# STM32N645 register map
File version: 1.0
CPU: CM55 r0p1, little endian, no MPU, FPU, vendor SysTick, 8 interrupt priority bits
Registers are 32-bit, read-write, reset 0x0 unless marked. A register's access mark holds for its fields unless they carry their own. Offsets are from the block's base; [hi:lo] are bit positions; {n}, {i} and the like mark numbered series; 'fields as' and 'values as' point back to an identical list.

## MDF1 — MDF register block
Base 0x42025000
Same registers: MDF1_S 0x52025000
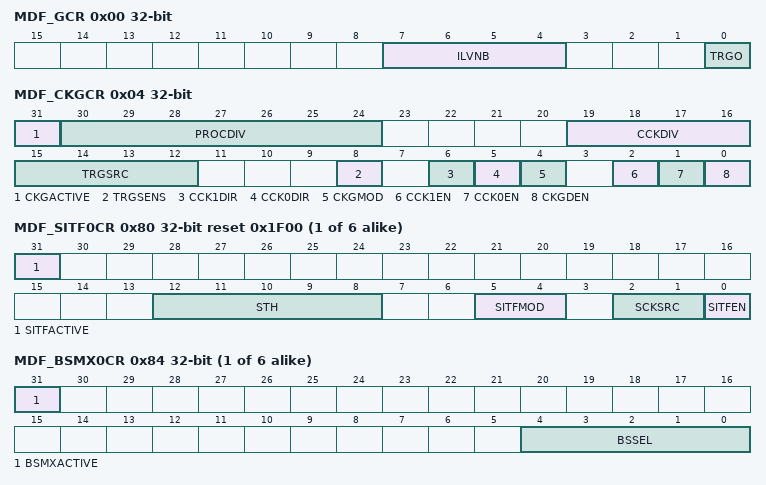
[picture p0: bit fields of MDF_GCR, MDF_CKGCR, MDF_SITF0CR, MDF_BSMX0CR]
0x00 MDF_GCR — MDF global control register
  [7:4] ILVNB — Interleaved number
    0=Interleaved-transfer mode disabled; 1=Data from DFLT0 and DFLT1 are interleaved; 2=Data from DFLT0, DFLT1 and DFLT2 are interleaved; 15=Data from DFLT0 to DFLT15 are interleaved
  [0] TRGO — Trigger output control
    0=Write 0 has no effect. Read 0 means that the trigger can be set again to 1.; 1=Write 1 generates a positive pulse on mdf_trgo signal and triggers the acquisition on the enabled filters having ACQMOD[2:0] = 0x1 and selecting TRGO as trigger. Read 1 means that the trigger pulse is still active.
0x04 MDF_CKGCR access per field — MDF clock generator control register
  [31] CKGACTIVE ro — Clock generator active flag
    0=The clock generator is not active and can be configured if needed; 1=The clock generator is active and protected fields cannot be configured
  [30:24] PROCDIV rw — Divider to control the serial interface clock
    0=mdf_ker_ck provided to the SITF; 1=mdf_ker_ck/2 provided to the SITF
  [19:16] CCKDIV rw — Divider to control the MDF_CCK clock
    0=The MDF_CCK clock is mdf_proc_ck; 1=The MDF_CCK clock is mdf_proc_ck / 2; 2=The MDF_CCK clock is mdf_proc_ck / 3; 15=The MDF_CCK clock is mdf_proc_ck / 16
  [15:12] TRGSRC rw — Digital filter trigger signal selection
    2=mdf_trg[0] selected; 3=mdf_trg[1] selected; 15=mdf_trg[13] selected
  [8] TRGSENS rw — CKGEN trigger sensitivity selection
    0=A rising edge event triggers the activation of CKGEN dividers; 1=A falling edge even triggers the activation of CKGEN dividers
  [6] CCK1DIR rw — MDF_CCK1 direction
    0=MDF_CCK1 pin direction is in input; 1=MDF_CCK1 pin direction is in output
  [5] CCK0DIR rw — MDF_CCK0 direction
    0=MDF_CCK0 pin direction is in input; 1=MDF_CCK0 pin direction is in output
  [4] CKGMOD rw — Clock generator mode
    0=The kernel clock is provided to the dividers as soon as CKGDEN is set to 1; 1=The kernel clock is provided to the dividers when CKGDEN is set to 1 and the trigger condition met
  [2] CCK1EN rw — MDF_CCK1 clock enable
    0=Bitstream clock not generated; 1=Bitstream clock generated on the MDF_CCK1 pad
  [1] CCK0EN rw — MDF_CCK0 clock enable
    0=Bitstream clock not generated; 1=Bitstream clock generated on the MDF_CCK0 pad
  [0] CKGDEN rw — CKGEN dividers enable
    0=CKGEN dividers disabled; 1=CKGEN dividers enabled
{0x80+0x80*i} MDF_SITF{i}CR access per field reset 0x1F00 (i=0..5) — MDF serial interface control register {i}
  [31] SITFACTIVE ro — Serial interface active flag
    0=The serial interface is not active and can be configured if needed; 1=The serial interface is active and protected fields cannot be configured
  [12:8] STH rw — Manchester symbol threshold/SPI threshold
  [5:4] SITFMOD rw — Serial interface type
    0=LF_MASTER SPI mode; 1=Normal SPI mode; 2=Manchester mode: rising edge = logic 0, falling edge = logic 1; 3=Manchester mode: rising edge = logic 1, falling edge = logic 0
  [2:1] SCKSRC rw — Serial clock source
    0=Serial clock source is MDF_CCK0; 1=Serial clock source is MDF_CCK1
  [0] SITFEN rw — Serial interface enable
    0=Serial interface disabled; 1=Serial interface enabled
{0x84+0x80*i} MDF_BSMX{i}CR access per field (i=0..5) — MDF bitstream matrix control register {i}
  [31] BSMXACTIVE ro — BSMX active flag
    0=BSMX is not active and can be configured if needed; 1=BSMX is active and protected fields cannot be configured
  [4:0] BSSEL rw — Bitstream Selection
    0=bs0_r provided to DFLTx and SCDx; 1=bs0_f provided to DFLTx and SCDx; 2=bs1_r provided to DFLTx and SCDx (if instantiated); 3=bs1_f provided to DFLTx and SCDx (if instantiated); 30=bs15_r provided to DFLTx and SCDx (if instantiated); 31=bs15_f provided to DFLTx and SCDx (if instantiated)
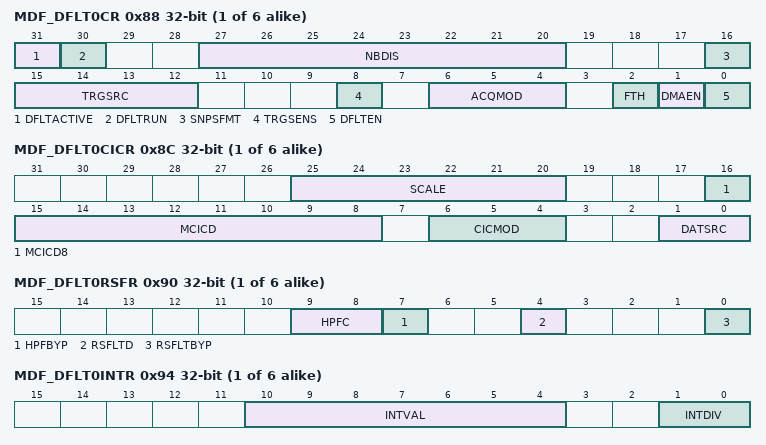
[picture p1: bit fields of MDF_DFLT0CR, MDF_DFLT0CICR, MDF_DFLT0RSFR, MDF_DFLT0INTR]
{0x88+0x80*i} MDF_DFLT{i}CR access per field (i=0..5) — MDF digital filter control register {i}
  [31] DFLTACTIVE ro — Digital filter active flag
    0=Digital filter not active (can be re-enabled again, via DFLTEN, if needed); 1=Digital filter active
  [30] DFLTRUN ro — Digital filter run status flag
    0=Digital filter not running and ready to accept a new trigger event; 1=Digital filter running
  [27:20] NBDIS rw — Number of samples to be discarded
    0=No sample discarded; 1=1 sample discarded
  [16] SNPSFMT rw — Snapshot data format
    0=Integrator counter (INT_CNT) not inserted into MDF_SNPSxDR, leaving a data resolution of 23 bits; 1=Integrator counter (INT_CNT) inserted at position [15:9] of MDF_SNPSxDR, leaving a data resolution of 16 bits
  [15:12] TRGSRC rw — Digital filter trigger signal selection
    0=TRGO selected; 1=OLDx event selected; 2=mdf_trg[0] selected; 15=mdf_trg[13] selected
  [8] TRGSENS rw — Digital filter trigger sensitivity selection
    0=A rising edge event triggers the acquisition; 1=A falling edge even triggers the acquisition
  [6:4] ACQMOD rw — Digital filter trigger mode
    0=Asynchronous continuous acquisition mode; 1=Asynchronous single-shot acquisition mode; 2=Synchronous continuous acquisition mode; 3=Synchronous, single-shot acquisition mode; 4=Window continuous acquisition mode; 5=Synchronous snapshot mode
  [2] FTH rw — RXFIFO Threshold selection
    0=RXFIFO threshold event generated when the RXFIFO is not empty; 1=RXFIFO threshold event generated when the RXFIFO is half-full
  [1] DMAEN rw — DMA requests enable
    0=DMA interface for the corresponding digital filter disabled; 1=DMA interface for the corresponding digital filter enabled
  [0] DFLTEN wo — Digital filter enable
    0=Acquisition immediately stopped; 1=Acquisition immediately started if ACQMOD[2:0] = 00x or 101, or acquisition started when the proper trigger event occurs if ACQMOD[2:0] = 01x or 100
{0x8C+0x80*i} MDF_DFLT{i}CICR (i=0..5) — MDF digital filter configuration register {i}
  [25:20] SCALE — Scaling factor selection
    0=0 dB; 1=+ 3.5 dB; 2=+ 6 dB or shift left by 1 bit; 24=+ 72 dB or shift left by 12 bits; 32=- 48.2 dB or shift right by 8 bits (default value); 33=- 44.6 dB; 34=- 42.1 dB or shift right by 7 bits; 35=- 38.6 dB; 46=- 6 dB or shift right by 1 bit; 47=- 2.5 dB
  [16] MCICD8 — CIC decimation ratio selection
    0=Decimation ratio is 2; 1=Decimation ratio is 2
  [15:8] MCICD — CIC decimation ratio selection
    0=Decimation ratio is 2; 1=Decimation ratio is 2
  [6:4] CICMOD — Select the CIC mode
    0=CIC split in two filters and MCIC configured in FastSinc filter; 1=CIC split in two filters and MCIC configured in Sinc less than sup>1 less than /sup> filter; 2=CIC split in two filters and MCIC configured in Sinc less than sup>2 less than /sup> filter; 3=CIC split in two filters and MCIC configured in Sinc less than sup>3 less than /sup> filter; 4=CIC configured in single Sinc less than sup>4 less than /sup> filter
  [1:0] DATSRC — Source data for the digital filter
    2=Stream coming from the ADCITF1 selected; 3=Stream coming from the ADCITF2 selected
{0x90+0x80*i} MDF_DFLT{i}RSFR (i=0..5) — MDF reshape filter configuration register {i}
  [9:8] HPFC — High-pass filter cut-off frequency
    0=Cut-off frequency = 0.000625 x F less than sub>PCM less than /sub>; 1=Cut-off frequency = 0.00125 x F less than sub>PCM less than /sub>; 2=Cut-off frequency = 0.00250 x F less than sub>PCM less than /sub>; 3=Cut-off frequency = 0.00950 x F less than sub>PCM less than /sub>
  [7] HPFBYP — High-pass filter bypass
    0=HPF not bypassed (default value); 1=HPF bypassed
  [4] RSFLTD — Reshaper filter decimation ratio
    0=Decimation ratio is 4 (default value); 1=Decimation ratio is 1
  [0] RSFLTBYP — Reshaper filter bypass
    0=Reshape filter not bypassed (default value); 1=Reshape filter bypassed
{0x94+0x80*i} MDF_DFLT{i}INTR (i=0..5) — MDF integrator configuration register {i}
  [10:4] INTVAL — Integration value selection
    0=The integration value is 1, meaning bypass mode (default after reset); 1=The integration value is 2
  [1:0] INTDIV — Integrator output division
    0=The integrator data outputs are divided by 128 (default value); 1=The integrator data outputs are divided by 32; 2=The integrator data outputs are divided by 4; 3=The integrator data outputs are not divided
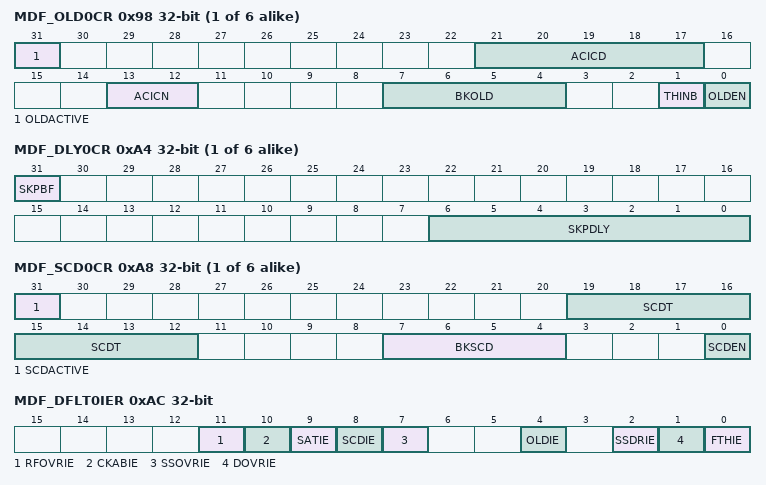
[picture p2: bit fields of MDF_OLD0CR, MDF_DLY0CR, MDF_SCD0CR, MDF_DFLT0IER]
{0x98+0x80*i} MDF_OLD{i}CR access per field (i=0..5) — MDF out-of limit detector control register {i}
  [31] OLDACTIVE ro — OLDx active flag
    0=OLDx not active and can be configured if needed; 1=OLDx active and protected fields cannot be configured
  [21:17] ACICD rw — OLDx CIC decimation ratio selection
    0=Decimation ratio is 1; 1=Decimation ratio is 2
  [13:12] ACICN rw — OLDx CIC order selection
    0=FastSinc filter type; 1=Sinc less than sup>1 less than /sup> filter type; 2=Sinc less than sup>2 less than /sup> filter type; 3=Sinc less than sup>3 less than /sup> filter type
  [7:4] BKOLD rw — Break signal assignment for out-of limit detector
  [1] THINB rw — Threshold In band
    0=The OLDx generates an event if the signal is lower than OLDTHL or higher than OLDTHH (default value); 1=The OLDx generates an event if the signal is lower than OLDTHH and higher than OLDTHL
  [0] OLDEN rw — OLDx enable
    0=OLDx disabled (default value); 1=OLDx enabled, including the ACIC filter working in continuous mode
{0x9C+0x80*i} MDF_OLD{i}THLR (i=0..5) — MDF OLD{i} low threshold register {i}
  [25:0] OLDTHL — OLD low threshold value
{0xA0+0x80*i} MDF_OLD{i}THHR (i=0..5) — MDF OLD{i} high threshold register {i}
  [25:0] OLDTHH — OLDx high threshold value
{0xA4+0x80*i} MDF_DLY{i}CR access per field (i=0..5) — MDF delay control register {i}
  [31] SKPBF ro — Skip busy flag
    0=MDF ready to accept a new value into SKPDLY[6:0]; 1=Last valid SKPDLY[6:0] still under processing
  [6:0] SKPDLY rw — Delay to apply to a bitstream
    0=No input sample skipped; 1=1 input sample skipped
{0xA8+0x80*i} MDF_SCD{i}CR access per field (i=0..5) — MDF short circuit detector control register {i}
  [31] SCDACTIVE ro — SCDx active flag
    0=SCDx not active and can be configured if needed; 1=SCDx active and protected fields cannot be configured
  [19:12] SCDT rw — SCDx threshold
    0=2 consecutive 1's or 0's generate an event; 1=2 consecutive 1's or 0's generate an event
  [7:4] BKSCD rw — Break signal assignment for short circuit detector
  [0] SCDEN rw — SCDx enable
    0=SCDx disabled; 1=SSCDx enabled,
0xAC MDF_DFLT0IER — MDF DFLT0 interrupt enable register 0
  [11] RFOVRIE — Reshape filter overrun interrupt enable
    0=Reshape filter overrun interrupt disabled; 1=Reshape filter overrun interrupt enabled
  [10] CKABIE — Clock absence detection interrupt enable
    0=Clock absence interrupt disabled; 1=Clock absence interrupt enabled
  [9] SATIE — Saturation detection interrupt enable
    0=Saturation interrupt disabled; 1=Saturation interrupt enabled
  [8] SCDIE — SCD0 interrupt enable
    0=SCD0 interrupt disabled; 1=SCD0 interrupt enabled
  [7] SSOVRIE — Snapshot overrun interrupt enable
    0=Snapshot overrun interrupt disabled; 1=Snapshot overrun interrupt enabled
  [4] OLDIE — OLD0 interrupt enable
    0=OLD0 event interrupt disabled; 1=OLD0 event interrupt enabled
  [2] SSDRIE — Snapshot data ready interrupt enable
    0=Snapshot data ready interrupt disabled; 1=Snapshot data ready interrupt enabled
  [1] DOVRIE — Data overflow interrupt enable
    0=Data overflow interrupt disabled; 1=Data overflow interrupt enabled
  [0] FTHIE — RXFIFO threshold interrupt enable
    0=RXFIFO threshold interrupt disabled; 1=RXFIFO threshold interrupt enabled
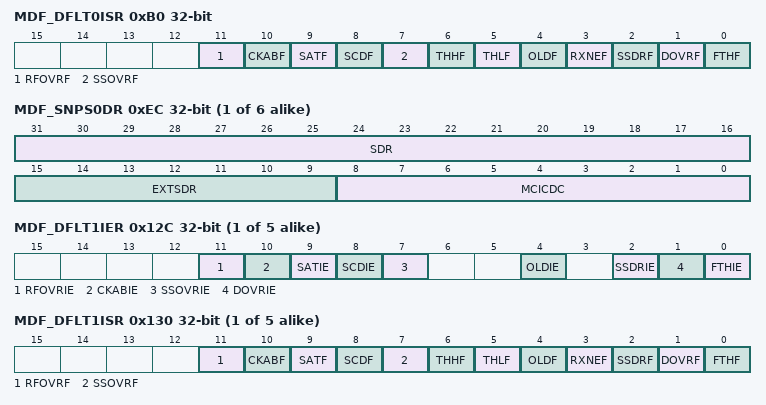
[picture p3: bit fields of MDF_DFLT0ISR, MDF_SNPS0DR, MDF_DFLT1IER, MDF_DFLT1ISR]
0xB0 MDF_DFLT0ISR access per field — MDF DFLT0 interrupt status register 0
  [11] RFOVRF rw — Reshape filter overrun detection flag
    0=Read 0 means that no reshape filter overrun is detected. Write 0 has no effect.; 1=Read 1 means that reshape filter overrun is detected. Write 1 clears this flag.
  [10] CKABF rw — Clock absence detection flag
    0=Read 0 means that no clock absence is detected. Write 0 has no effect.; 1=Read 1 means that a clock absence is detected. Write 1 clears this flag.
  [9] SATF rw — Saturation detection flag
    0=Read 0 means that no saturation is detected. Write 0 has no effect.; 1=Read 1 means that a saturation is detected. Write 1 clears this flag.
  [8] SCDF rw — Short-circuit detector flag
    0=Read 0 means that no SCD0 event is detected. Write 0 has no effect.; 1=Read 1 means that a SCD0 event is detected. Write 1 clears this flag.
  [7] SSOVRF rw — Snapshot overrun flag
    0=Read 0 means that no snapshot overrun event is detected. Write 0 has no effect.; 1=Read 1 means that a snapshot overrun event is detected. Write 1 clears this flag.
  [6] THHF ro — High-threshold status flag
    0=The signal was lower than OLDTHH when the last OLD0 event occurred; 1=The signal was higher than OLDTHH when the last OLD0 event occurred
  [5] THLF ro — Low-threshold status flag
    0=The signal was higher than OLDTHL when the last OLD0 event occurred; 1=The signal was lower than OLDTHL when the last OLD0 event occurred
  [4] OLDF rw — OLD0 flag
    0=Read 0 means that no OLD0 event is detected. Write 0 has no effect.; 1=Read 1 means that an OLD0 event is detected Write 1 clears THHF, THLF and OLDF
  [3] RXNEF ro — RXFIFO not-empty flag
    0=RXFIFO empty; 1=RXFIFO not empty
  [2] SSDRF rw — Snapshot data ready flag
    0=Read 0 means that no data is available. Write 0 has no effect.; 1=Read 1 means that a new data is available. Write 1 clears this flag.
  [1] DOVRF rw — Data overflow flag
    0=Read 0 means that no overflow is detected. Write 0 has no effect.; 1=Read 1 means that an overflow is detected; Write 1 clears this flag
  [0] FTHF ro — RXFIFO threshold flag
    0=RXFIFO threshold not reached; 1=RXFIFO threshold reached
{0xB4+0x80*i} MDF_OEC{i}CR (i=0..5) — MDF offset error compensation control register {i}
  [25:0] OFFSET — Offset error compensation
{0xEC+0x80*i} MDF_SNPS{i}DR ro (i=0..5) — MDF snapshot data register {i}
  [31:16] SDR — Contains the 16 MSB of the last valid data processed by the digital filter.
  [15:9] EXTSDR — Extended data size
  [8:0] MCICDC — Contains the MCIC decimation counter value when the last trigger event occurs (MCIC_CNT)
{0xF0+0x80*i} MDF_DFLT{i}DR ro (i=0..5) — MDF digital filter data register {i}
  [31:8] DR — Data processed by digital filter
{0xAC+0x80*i} MDF_DFLT{i}IER (i=1..5) — MDF DFLT{i} interrupt enable register {i}
  [11] RFOVRIE — Reshape filter overrun interrupt enable
    values as MDF_DFLT0IER.RFOVRIE
  [10] CKABIE — Clock absence detection interrupt enable
    values as MDF_DFLT0IER.CKABIE
  [9] SATIE — Saturation detection interrupt enable
    values as MDF_DFLT0IER.SATIE
  [8] SCDIE — SCDx interrupt enable
    0=SCDx interrupt disabled; 1=SCDx interrupt enabled
  [7] SSOVRIE — Snapshot overrun interrupt enable
    values as MDF_DFLT0IER.SSOVRIE
  [4] OLDIE — OLDx interrupt enable
    0=OLDx event interrupt disabled; 1=OLDx event interrupt enabled
  [2] SSDRIE — Snapshot data ready interrupt enable
    values as MDF_DFLT0IER.SSDRIE
  [1] DOVRIE — Data overflow interrupt enable
    values as MDF_DFLT0IER.DOVRIE
  [0] FTHIE — RXFIFO threshold interrupt enable
    values as MDF_DFLT0IER.FTHIE
{0xB0+0x80*i} MDF_DFLT{i}ISR access per field (i=1..5) — MDF DFLT{i} interrupt status register {i}
  [11] RFOVRF rw — Reshape filter overrun detection flag
    values as MDF_DFLT0ISR.RFOVRF
  [10] CKABF rw — Clock absence detection flag
    values as MDF_DFLT0ISR.CKABF
  [9] SATF rw — Saturation detection flag
    values as MDF_DFLT0ISR.SATF
  [8] SCDF rw — Short-circuit detector flag
    0=Read 0 means that no SCD event is detected. Write 0 has no effect.; 1=Read 1 means that a SCD event is detected. Write 1 clears this flag.
  [7] SSOVRF rw — Snapshot overrun flag
    values as MDF_DFLT0ISR.SSOVRF
  [6] THHF ro — High-threshold status flag
    0=The signal was lower than OLDTHH when the last OLDx event occurred; 1=The signal was higher than OLDTHH when the last OLDx event occurred
  [5] THLF ro — Low-threshold status flag
    0=The signal was higher than OLDTHL when the last OLDx event occurred; 1=The signal was lower than OLDTHL when the last OLDx event occurred
  [4] OLDF rw — OLDx flag
    0=Read 0 means that no OLDx event is detected. Write 0 has no effect.; 1=Read 1 means that an OLDx event is detected Write 1 clears THHF, THLF and OLDF
  [3] RXNEF ro — RXFIFO not-empty flag
    0=RXFIFO empty; 1=RXFIFO not empty
  [2] SSDRF rw — Snapshot data ready flag
    values as MDF_DFLT0ISR.SSDRF
  [1] DOVRF rw — Data overflow flag
    values as MDF_DFLT0ISR.DOVRF
  [0] FTHF ro — RXFIFO threshold flag
    0=RXFIFO threshold not reached; 1=RXFIFO threshold reached
